# TM4C1236H6PM register map
Vendor: Texas Instruments; File version: 11073
CPU: CM4 r1p2, little endian, no MPU, no FPU, 0x3 interrupt priority bits, 0x0 interrupts
Registers are 32-bit, read-write, no defined reset value unless marked. A register's access mark holds for its fields unless they carry their own. Offsets are from the block's base; [hi:lo] are bit positions; 'fields as' and 'values as' point back to an identical list.

## WATCHDOG0 — Register map for WATCHDOG0 peripheral
Base 0x40000000; register names take the prefix WATCHDOG0
0x00 LOAD — Watchdog Load
  [31:0] WDT_LOAD — Watchdog Load Value
0x04 VALUE — Watchdog Value
  [31:0] WDT_VALUE
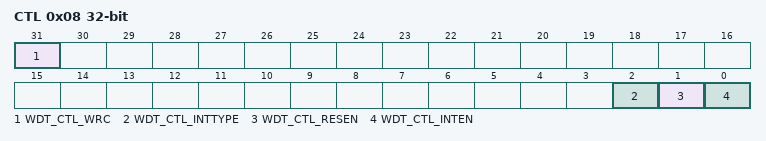
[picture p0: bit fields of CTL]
0x08 CTL — Watchdog Control
  [31] WDT_CTL_WRC — Write Complete
  [2] WDT_CTL_INTTYPE — Watchdog Interrupt Type
  [1] WDT_CTL_RESEN — Watchdog Reset Enable
  [0] WDT_CTL_INTEN — Watchdog Interrupt Enable
0x0C ICR wo — Watchdog Interrupt Clear
  [31:0] WDT_ICR
0x10 RIS — Watchdog Raw Interrupt Status
  [0] WDT_RIS_WDTRIS
0x14 MIS — Watchdog Masked Interrupt Status
  [0] WDT_MIS_WDTMIS
0x418 TEST — Watchdog Test
  [8] WDT_TEST_STALL — Watchdog Stall Enable
0xC00 LOCK — Watchdog Lock
  [31:0] WDT_LOCK
    0=WDT_LOCK_UNLOCKED (Unlocked); 1=WDT_LOCK_LOCKED (Locked); 0x1ACCE551=WDT_LOCK_UNLOCK (Unlocks the watchdog timer)

## WATCHDOG1 — Register map for WATCHDOG0 peripheral
Base 0x40001000; register names take the prefix WATCHDOG1
Registers as WATCHDOG0.

## GPIOA — Register map for GPIOA peripheral
Base 0x40004000; register names take the prefix GPIOA
0x3FC DATA — GPIO Data
0x400 DIR — GPIO Direction
0x404 IS — GPIO Interrupt Sense
0x408 IBE — GPIO Interrupt Both Edges
0x40C IEV — GPIO Interrupt Event
0x410 IM — GPIO Interrupt Mask
  [7:0] GPIO_IM_GPIO — GPIO Interrupt Mask Enable
0x414 RIS — GPIO Raw Interrupt Status
  [7:0] GPIO_RIS_GPIO — GPIO Interrupt Raw Status
0x418 MIS — GPIO Masked Interrupt Status
  [7:0] GPIO_MIS_GPIO
0x41C ICR wo — GPIO Interrupt Clear
  [7:0] GPIO_ICR_GPIO
0x420 AFSEL — GPIO Alternate Function Select
0x500 DR2R — GPIO 2-mA Drive Select
0x504 DR4R — GPIO 4-mA Drive Select
0x508 DR8R — GPIO 8-mA Drive Select
0x50C ODR — GPIO Open Drain Select
0x510 PUR — GPIO Pull-Up Select
0x514 PDR — GPIO Pull-Down Select
0x518 SLR — GPIO Slew Rate Control Select
0x51C DEN — GPIO Digital Enable
0x520 LOCK — GPIO Lock
  [31:0] GPIO_LOCK
    0=GPIO_LOCK_UNLOCKED (The GPIOCR register is unlocked and may be modified); 1=GPIO_LOCK_LOCKED (The GPIOCR register is locked and may not be modified); 0x4C4F434B=GPIO_LOCK_KEY (Unlocks the GPIO_CR register)
0x524 CR ro — GPIO Commit
0x528 AMSEL — GPIO Analog Mode Select
0x52C PCTL — GPIO Port Control
0x530 ADCCTL — GPIO ADC Control
0x534 DMACTL — GPIO DMA Control

## GPIOB — Register map for GPIOA peripheral
Base 0x40005000; register names take the prefix GPIOB
Registers as GPIOA.

## GPIOC — Register map for GPIOA peripheral
Base 0x40006000; register names take the prefix GPIOC
Registers as GPIOA; these are added or differ:
0x520 LOCK — GPIO Lock
  fields as GPIOA.LOCK

## GPIOD — Register map for GPIOA peripheral
Base 0x40007000; register names take the prefix GPIOD
Registers as GPIOA.

## GPIOE — Register map for GPIOA peripheral
Base 0x40024000; register names take the prefix GPIOE
Registers as GPIOA.

## GPIOF — Register map for GPIOA peripheral
Base 0x40025000; register names take the prefix GPIOF
Registers as GPIOA.

## GPIOG — Register map for GPIOA peripheral
Base 0x40026000; register names take the prefix GPIOG
Registers as GPIOA.

## GPIOA_AHB — Register map for GPIOA peripheral
Base 0x40058000; register names take the prefix GPIOA_AHB
Registers as GPIOA.

## GPIOB_AHB — Register map for GPIOA peripheral
Base 0x40059000; register names take the prefix GPIOB_AHB
Registers as GPIOA.

## GPIOC_AHB — Register map for GPIOA peripheral
Base 0x4005A000; register names take the prefix GPIOC_AHB
Registers as GPIOA.

## GPIOD_AHB — Register map for GPIOA peripheral
Base 0x4005B000; register names take the prefix GPIOD_AHB
Registers as GPIOA.

## GPIOE_AHB — Register map for GPIOA peripheral
Base 0x4005C000; register names take the prefix GPIOE_AHB
Registers as GPIOA.

## GPIOF_AHB — Register map for GPIOA peripheral
Base 0x4005D000; register names take the prefix GPIOF_AHB
Registers as GPIOA.

## GPIOG_AHB — Register map for GPIOA peripheral
Base 0x4005E000; register names take the prefix GPIOG_AHB
Registers as GPIOA.
